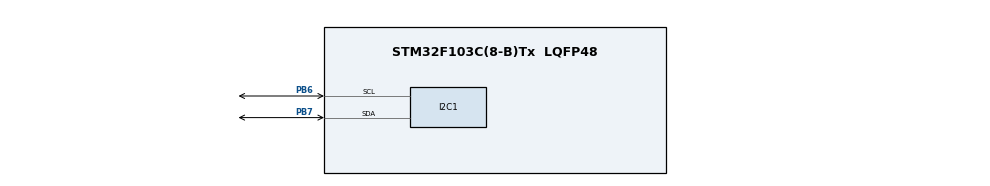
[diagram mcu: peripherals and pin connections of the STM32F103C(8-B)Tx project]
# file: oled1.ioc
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I2C1.I2C_Mode=I2C_Fast
Mcu.Family=STM32F1
Mcu.Name=STM32F103C(8-B)Tx
Mcu.Package=LQFP48
NVIC.PriorityGroup=NVIC_PRIORITYGROUP_4
PA13.Mode=Serial_Wire
PA13.Signal=SYS_JTMS-SWDIO
PA14.Mode=Serial_Wire
PA14.Signal=SYS_JTCK-SWCLK
PB6.Mode=I2C
PB6.Signal=I2C1_SCL
PB7.Mode=I2C
PB7.Signal=I2C1_SDA
ProjectManager.HeapSize=0x200
ProjectManager.StackSize=0x400
ProjectManager.TargetToolchain=STM32CubeIDE
RCC.APB1Freq_Value=8000000
RCC.APB2Freq_Value=8000000
board=custom

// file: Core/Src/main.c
/* USER CODE BEGIN Header */
/**
  ******************************************************************************
  * @file           : main.c
  * @brief          : Main program body
  ******************************************************************************
  * @attention
  *
  * Copyright (c) 2022 STMicroelectronics.
  * All rights reserved.
  *
  * This software is licensed under terms that can be found in the LICENSE file
  * in the root directory of this software component.
  * If no LICENSE file comes with this software, it is provided AS-IS.
  *
  ******************************************************************************
  */
/* USER CODE END Header */
#include "main.h"

/* USER CODE BEGIN Includes */
#include "fonts.h"
#include "ssd1306.h"
/* USER CODE END Includes */

I2C_HandleTypeDef hi2c1;

void SystemClock_Config(void);
static void MX_GPIO_Init(void);
static void MX_I2C1_Init(void);

int main(void)
{

  /* MCU Configuration--------------------------------------------------------*/

  /* Reset of all peripherals, Initializes the Flash interface and the Systick. */
  HAL_Init();

  /* Configure the system clock */
  SystemClock_Config();

  /* Initialize all configured peripherals */
  MX_GPIO_Init();
  MX_I2C1_Init();
  /* USER CODE BEGIN 2 */

  SSD1306_Init();
  char snum[5];
 /* SSD1306_GotoXY (45,10); //isimler için koordinatlar
  SSD1306_Puts("ECE", &Font_11x18, 1); //belirtilen koordinata bunu koy
  SSD1306_GotoXY(35,30);
  SSD1306_Puts("CINAR", &Font_11x18, 1);
  SSD1306_UpdateScreen(); // ekrana yazılması için girilen kodları çalıştıran sağlayan fonksiyon
  HAL_Delay(500);

  SSD1306_Scrolldiagright(0,0);
  HAL_Delay(2500);
  SSD1306_Scrolldiagleft(0,0);
  HAL_Delay (1000);
  SSD1306_Stopscroll();
  SSD1306_Clear();
  HAL_Delay(1000);
  SSD1306_GotoXY(35,10);
  SSD1306_Puts ("SCORE", &Font_11x18, 1);
  SSD1306_UpdateScreen();
  SSD1306_Scrolldiagleft(0,0);
  HAL_Delay(2500);
  SSD1306_Stopscroll();
  SSD1306_Clear();*/

  /* USER CODE END 2 */

  /* Infinite loop */
  /* USER CODE BEGIN WHILE */
  while (1)
  {
	    SSD1306_GotoXY (45,10); //isimler için koordinatlar
	    SSD1306_Puts("ECE", &Font_11x18, 1); //belirtilen koordinata bunu koy
	    SSD1306_GotoXY(35,30);
	    SSD1306_Puts("CINAR", &Font_11x18, 1);
	    SSD1306_UpdateScreen(); // ekrana yazılması için girilen kodları çalıştıran sağlayan fonksiyon
	    HAL_Delay(500);

	    SSD1306_Scrolldiagright(0,0);
	    HAL_Delay(2500);
	   /* SSD1306_Scrolldiagleft(0,0);
	    HAL_Delay (1000);*/
	    SSD1306_Stopscroll();
	    SSD1306_Clear();
	    HAL_Delay(1000);
	    SSD1306_GotoXY(35,10);
	    SSD1306_Puts ("SCORE", &Font_11x18, 1);
	    SSD1306_UpdateScreen();
	    SSD1306_Scrolldiagleft(0,0);
	    HAL_Delay(2500);
	    SSD1306_Stopscroll();
	    SSD1306_Clear();

	  for(int x=1; x<=100;x++)
	  {
		  itoa(x,snum,10);
		  SSD1306_GotoXY(0,30);
		  SSD1306_Puts ("          ", &Font_16x26,1);
		  SSD1306_UpdateScreen();
		  if( x<10 )
		  {
			  SSD1306_GotoXY(53,30);
		  }
		  else if (x<100)
		  {
			  SSD1306_GotoXY(45,30);
		  }
		  else
		  {
			  SSD1306_GotoXY(37,30);
		  }
		 SSD1306_Puts(snum, &Font_16x26, 1);
		 SSD1306_UpdateScreen();
		 HAL_Delay(400);
		 SSD1306_Clear();
		 HAL_Delay(100);

	  }
	  break ;
    /* USER CODE END WHILE */

  }
}

void SystemClock_Config(void)
{
  RCC_OscInitTypeDef RCC_OscInitStruct = {0};
  RCC_ClkInitTypeDef RCC_ClkInitStruct = {0};

  /** Initializes the RCC Oscillators according to the specified parameters
  * in the RCC_OscInitTypeDef structure.
  */
  RCC_OscInitStruct.OscillatorType = RCC_OSCILLATORTYPE_HSI;
  RCC_OscInitStruct.HSIState = RCC_HSI_ON;
  RCC_OscInitStruct.HSICalibrationValue = RCC_HSICALIBRATION_DEFAULT;
  RCC_OscInitStruct.PLL.PLLState = RCC_PLL_NONE;
  if (HAL_RCC_OscConfig(&RCC_OscInitStruct) != HAL_OK)
  {
    Error_Handler();
  }

  /** Initializes the CPU, AHB and APB buses clocks
  */
  RCC_ClkInitStruct.ClockType = RCC_CLOCKTYPE_HCLK|RCC_CLOCKTYPE_SYSCLK
                              |RCC_CLOCKTYPE_PCLK1|RCC_CLOCKTYPE_PCLK2;
  RCC_ClkInitStruct.SYSCLKSource = RCC_SYSCLKSOURCE_HSI;
  RCC_ClkInitStruct.AHBCLKDivider = RCC_SYSCLK_DIV1;
  RCC_ClkInitStruct.APB1CLKDivider = RCC_HCLK_DIV1;
  RCC_ClkInitStruct.APB2CLKDivider = RCC_HCLK_DIV1;

  if (HAL_RCC_ClockConfig(&RCC_ClkInitStruct, FLASH_LATENCY_0) != HAL_OK)
  {
    Error_Handler();
  }
}

static void MX_I2C1_Init(void)
{

  hi2c1.Instance = I2C1;
  hi2c1.Init.ClockSpeed = 400000;
  hi2c1.Init.DutyCycle = I2C_DUTYCYCLE_2;
  hi2c1.Init.OwnAddress1 = 0;
  hi2c1.Init.AddressingMode = I2C_ADDRESSINGMODE_7BIT;
  hi2c1.Init.DualAddressMode = I2C_DUALADDRESS_DISABLE;
  hi2c1.Init.OwnAddress2 = 0;
  hi2c1.Init.GeneralCallMode = I2C_GENERALCALL_DISABLE;
  hi2c1.Init.NoStretchMode = I2C_NOSTRETCH_DISABLE;
  if (HAL_I2C_Init(&hi2c1) != HAL_OK)
  {
    Error_Handler();
  }

}

static void MX_GPIO_Init(void)
{

  /* GPIO Ports Clock Enable */
  __HAL_RCC_GPIOA_CLK_ENABLE();
  __HAL_RCC_GPIOB_CLK_ENABLE();

}

void Error_Handler(void)
{
  __disable_irq();
  while (1)
  {
  }
}
